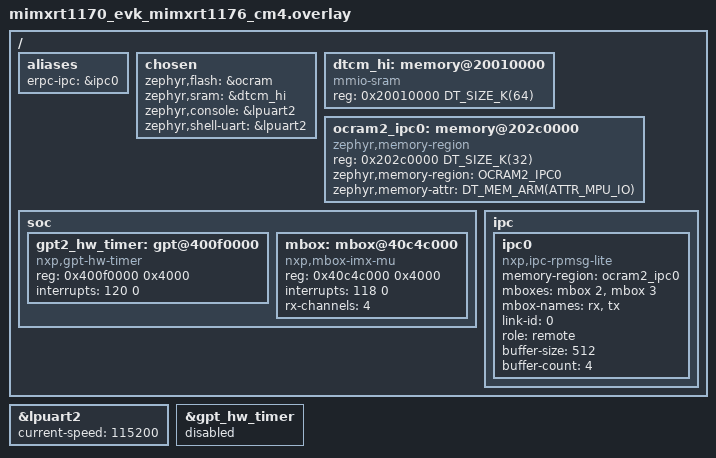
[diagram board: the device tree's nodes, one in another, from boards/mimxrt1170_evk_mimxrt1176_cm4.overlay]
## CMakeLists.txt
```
# Copyright 2026 NXP
#
# SPDX-License-Identifier: Apache-2.0

cmake_minimum_required(VERSION 3.20.0)
find_package(Zephyr REQUIRED HINTS $ENV{ZEPHYR_BASE})
project(tee_dec_multicore_remote)

target_sources(app PRIVATE src/main.c)
```

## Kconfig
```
# Copyright 2026 NXP
# SPDX-License-Identifier: Apache-2.0

mainmenu "Pipelines on two cores described in the devicetree, remote core"

config CHECK_STACK_SIZE
	int "Stack size of the thread serving the checking pipeline"
	default 4096
	help
	  The thread negotiates the checking pipeline and runs it.

source "Kconfig.zephyr"
```

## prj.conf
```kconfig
CONFIG_PRINTK=y
CONFIG_LOG=y
CONFIG_LOG_MODE_MINIMAL=y

# main() negotiates and runs the decoding pipeline
CONFIG_MAIN_STACK_SIZE=6000
CONFIG_HEAP_MEM_POOL_SIZE=8192

CONFIG_MPIPE=y
CONFIG_MPIPE_STRUCTURE_MAX_FIELDS=3
CONFIG_MPIPE_BASE=y
CONFIG_MPIPE_BASE_APP_SRC=y
CONFIG_MPIPE_BASE_APP_SINK=y
CONFIG_MPIPE_BASE_CAPS_FILTER=y
CONFIG_MPIPE_IMG=y
CONFIG_MPIPE_IMG_JPEG_DECODER=y
CONFIG_MPIPE_VID=y
CONFIG_MPIPE_VID_OVERLAY=y
CONFIG_MPIPE_PIPELINE_SERVER=y
CONFIG_MPIPE_VID_PIPELINE_SERVER=y
CONFIG_MPIPE_ERPC_VID_SERVER=y

# One thread per pipeline, idle: the threads serving the pipelines stream
CONFIG_MPIPE_THREADS_NUM=2
CONFIG_MPIPE_THREAD_STACK_SIZE=2048
# The headers wrapping the buffers of the other core
CONFIG_MPIPE_NET_BUF_POOL_COUNT=4

# Every frame lives in the memory of the other core: the pools of this one
# are never allocated from and are given the smallest size there is
CONFIG_MPIPE_BASE_APP_SRC_BUF_SZ=4
CONFIG_MPIPE_BASE_APP_SRC_POOL_NUM=1
CONFIG_MPIPE_IMG_JPEG_DECODER_MAX_OUT_FRAME_SIZE=4
CONFIG_VIDEO_BUFFER_POOL_NUM_MAX=1
CONFIG_VIDEO_BUFFER_POOL_HEAP_SIZE=1024

# The image runs from the 128K of code RAM of the core
CONFIG_CBPRINTF_NANO=y

# eRPC servers over the IPC service, one per served pipeline, nothing from the heap
CONFIG_ERPC=y
CONFIG_ERPC_TRANSPORT_IPC_SERVICE=y
CONFIG_ERPC_ALLOCATION_POLICY_STATIC=y
CONFIG_ERPC_CODEC_COUNT=2
CONFIG_ERPC_DEFAULT_BUFFER_SIZE=4096
CONFIG_MPIPE_ERPC_SERVER=y
CONFIG_MPIPE_ERPC_SERVERS_NUM=2

# RPMsg-Lite
CONFIG_RL_API_HAS_ZEROCOPY=y
CONFIG_RL_USE_STATIC_API=y
# The other core opens the link when it creates its first channel, which
# can be seconds after the boot: wait for it longer than the default 5 s
CONFIG_IPC_SERVICE_BACKEND_RPMSG_LITE_LINK_UP_TIMEOUT_MS=60000
CONFIG_TIMESLICE_SIZE=1

# The bus carries end-of-stream and errors, never data: it needs neither
# zbus priority boost nor zbus logging of its own.
CONFIG_ZBUS_PRIORITY_BOOST=n
CONFIG_ZBUS_LOG_LEVEL_ERR=y
```

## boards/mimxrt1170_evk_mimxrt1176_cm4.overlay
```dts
/*
 * Copyright 2026 NXP
 *
 * SPDX-License-Identifier: Apache-2.0
 */

#include <zephyr/dt-bindings/ipc_service/static_vrings.h>
#include <zephyr/dt-bindings/memory-attr/memory-attr-arm.h>

/ {
	aliases {
		/* The IPC instance eRPC runs over */
		erpc-ipc = &ipc0;
	};

	chosen {
		/*
		 * The M7 sees the two TCMs of the M4 as one block at 0x20200000,
		 * the ITCM then the DTCM, and loads the image there. The code
		 * takes the ITCM. The initial values of the data follow it, so
		 * they land in the lower half of the DTCM.
		 */
		zephyr,flash = &ocram;
		/* The upper half of the DTCM: the RAM must not overlap those values */
		zephyr,sram = &dtcm_hi;
		zephyr,console = &lpuart2;
		zephyr,shell-uart = &lpuart2;

		/* Delete ipc chosen property where old IPM mailbox driver below is
		 * configured.
		 */
		/delete-property/ zephyr,ipc;
		/delete-property/ zephyr,ipc_shm;
	};

	dtcm_hi: memory@20010000 {
		compatible = "mmio-sram";
		reg = <0x20010000 DT_SIZE_K(64)>;
	};

	/* Define memory regions for IPC
	 * Note that shared memory must have specific MPU attributes set.
	 */
	ocram2_ipc0: memory@202c0000 {
		compatible = "zephyr,memory-region", "mmio-sram";
		reg = <0x202c0000 DT_SIZE_K(32)>;
		zephyr,memory-region = "OCRAM2_IPC0";
		zephyr,memory-attr = <DT_MEM_ARM(ATTR_MPU_IO)>;
	};

	soc {
		/delete-node/ gpt@400f0000;

		/* Replace GPT2 with another GPT kernel timer */
		gpt2_hw_timer: gpt@400f0000 {
			compatible = "nxp,gpt-hw-timer";
			reg = <0x400f0000 0x4000>;
			interrupts = <120 0>;
			status = "okay";
		};

		/* Delete IPM Driver node nxp,imx-mu */
		/delete-node/ mailbox@40c4c000;

		/* Attach MBOX driver to MU Unit */
		mbox: mbox@40c4c000 {
			compatible = "nxp,mbox-imx-mu";
			reg = <0x40c4c000 0x4000>;
			interrupts = <118 0>;
			rx-channels = <4>;
			#mbox-cells = <1>;
			status = "okay";
		};
	};

	ipc {
		/delete-node/ ipc0;

		ipc0: ipc0 {
			compatible = "nxp,ipc-rpmsg-lite";
			memory-region = <&ocram2_ipc0>;
			mboxes = <&mbox 2>, <&mbox 3>;
			mbox-names = "rx", "tx";
			link-id = <0>;
			role = "remote";
			buffer-size = <512>;
			buffer-count = <4>;
			status = "okay";
		};
	};
};

/* Enable secondary LPUART */
&lpuart2 {
	status = "okay";
	current-speed = <115200>;
};

/* Disable primary GPT timer */
&gpt_hw_timer {
	status = "disabled";
};
```

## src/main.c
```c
/*
 * Copyright 2026 NXP
 *
 * SPDX-License-Identifier: Apache-2.0
 */

/*
 * The two pipelines this core runs for the pipeline of the other core are
 * described in pipeline.dtsi and built at boot. The application puts each
 * behind the server its client element talks to, and brings what this core
 * draws on the frames and what it checks in them.
 */

#include <zephyr/devicetree.h>
#include <zephyr/kernel.h>
#include <zephyr/logging/log.h>
#include <zephyr/net_buf.h>
#include <zephyr/sys/util.h>

#include <zephyr/mpipe/base/mpipe_app_sink.h>
#include <zephyr/mpipe/base/mpipe_app_src.h>
#include <zephyr/mpipe/mpipe_dt.h>
#include <zephyr/mpipe/utils/mpipe_pipeline_server.h>
#include <zephyr/mpipe/vid/mpipe_vid_draw.h>
#include <zephyr/mpipe/erpc/mpipe_erpc_vid.h>

LOG_MODULE_REGISTER(main, CONFIG_LOG_DEFAULT_LEVEL);

/* The mark of this core on every frame: a bar growing with the frames it decoded */
/*
 * IPC endpoints of the two served pipelines: the client elements name them in
 * the devicetree of the other core
 */
#define DEC_ENDPOINT   "mpipe_dec"
#define CHECK_ENDPOINT "mpipe_check"

#define BAR_HEIGHT 6U
#define BAR_STEP   2U

static struct mpipe_pipeline_server check_server;
/* Each endpoint serves one pipeline: its function 0 */
static struct mpipe_pipeline_server *const check_servers[] = {&check_server};

void sample_draw_bar(uint8_t *frame, uint16_t width, uint16_t height, uint32_t pixfmt,
		     const struct net_buf *in, void *user_data)
{
	static uint32_t frames;
	struct mpipe_vid_rect bar = {
		.x0 = 0,
		.y0 = (int32_t)height - (int32_t)BAR_HEIGHT,
		.x1 = (int32_t)((frames * BAR_STEP) % width),
		.y1 = (int32_t)height,
	};

	ARG_UNUSED(in);
	ARG_UNUSED(user_data);

	frames++;
	(void)mpipe_vid_draw_fill(frame, width, height, pixfmt, &bar, 0xFFFF0000U);
}

/* The checking pipeline reports once for this many frames */
#define CHECK_REPORT_FRAMES 30U

/* A JPEG frame starts with the SOI marker and ends with the EOI marker */
void sample_check_frame(const struct net_buf *buf, void *user_data)
{
	static uint32_t frames;
	static uint32_t damaged;
	const uint8_t *data = buf->data;
	size_t len = buf->len;

	ARG_UNUSED(user_data);

	if (len < 4U || data[0] != 0xFFU || data[1] != 0xD8U || data[len - 2U] != 0xFFU ||
	    data[len - 1U] != 0xD9U) {
		damaged++;
	}

	frames++;
	if ((frames % CHECK_REPORT_FRAMES) == 0U) {
		LOG_INF("Checked %u frames, %u damaged", (unsigned int)frames,
			(unsigned int)damaged);
	}
}

/* The checking pipeline streams on this thread, the decoding one on main() */
static void check_thread(void *p1, void *p2, void *p3)
{
	ARG_UNUSED(p1);
	ARG_UNUSED(p2);
	ARG_UNUSED(p3);

	(void)mpipe_erpc_vid_server_run(check_servers, ARRAY_SIZE(check_servers), CHECK_ENDPOINT);
}

K_THREAD_STACK_DEFINE(check_stack, CONFIG_CHECK_STACK_SIZE);

int main(void)
{
	static struct mpipe_pipeline_server dec_server;
	static struct mpipe_pipeline_server *const dec_servers[] = {&dec_server};
	static struct k_thread check;
	int ret;

	LOG_INF("Remote started");

	ret = mpipe_pipeline_server_init(
		&dec_server, MPIPE_DT_PIPELINE_GET(DT_NODELABEL(decoding_pipeline)),
		(struct mpipe_app_src *)MPIPE_DT_ELEMENT_GET(DT_NODELABEL(decoding_src)),
		(struct mpipe_app_sink *)MPIPE_DT_ELEMENT_GET(DT_NODELABEL(decoding_sink)));
	if (ret != 0) {
		LOG_ERR("Failed to serve the decoding pipeline (%d)", ret);
		goto err;
	}

	/* The pipeline ends here: its app_sink hands nothing back to the client */
	ret = mpipe_pipeline_server_init(
		&check_server, MPIPE_DT_PIPELINE_GET(DT_NODELABEL(checking_pipeline)),
		(struct mpipe_app_src *)MPIPE_DT_ELEMENT_GET(DT_NODELABEL(checking_src)), NULL);
	if (ret != 0) {
		LOG_ERR("Failed to serve the checking pipeline (%d)", ret);
		goto err;
	}

	/* Each server has its endpoint: the two clients never wait for each other */
	(void)k_thread_create(&check, check_stack, K_THREAD_STACK_SIZEOF(check_stack),
			      check_thread, NULL, NULL, NULL, CONFIG_MAIN_THREAD_PRIORITY, 0,
			      K_NO_WAIT);

	(void)mpipe_erpc_vid_server_run(dec_servers, ARRAY_SIZE(dec_servers), DEC_ENDPOINT);

err:
	LOG_ERR("Aborting sample");
	return 0;
}
```
